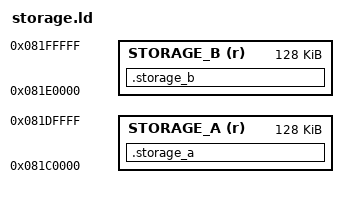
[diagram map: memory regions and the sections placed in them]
/*
 * AUTO-GENERATED by storage/codegen — DO NOT EDIT.
 * Registry CRC32: 0xF1EBE15C
 *
 * INCLUDE this from the per-core linker script (e.g. CM4's
 * stm32h745xx_flash_CM4.ld) to reserve two flash sectors for the
 * ping-pong storage region. The .storage_a / .storage_b output
 * sections place the linker-decorated constants from
 * generated/storage/storage_data.c into sectors A and B.
 */

MEMORY
{
    STORAGE_A (r) : ORIGIN = 0x081C0000, LENGTH = 131072
    STORAGE_B (r) : ORIGIN = 0x081E0000, LENGTH = 131072
}

SECTIONS
{
    .storage_a (NOLOAD) : ALIGN(32) {
        KEEP(*(.storage_a))
    } > STORAGE_A

    .storage_b (NOLOAD) : ALIGN(32) {
        KEEP(*(.storage_b))
    } > STORAGE_B
}

ASSERT(SIZEOF(.storage_a) <= LENGTH(STORAGE_A),
       "storage_a exceeds sector A — bump sector size or trim groups");
ASSERT(SIZEOF(.storage_b) <= LENGTH(STORAGE_B),
       "storage_b exceeds sector B — bump sector size or trim groups");
